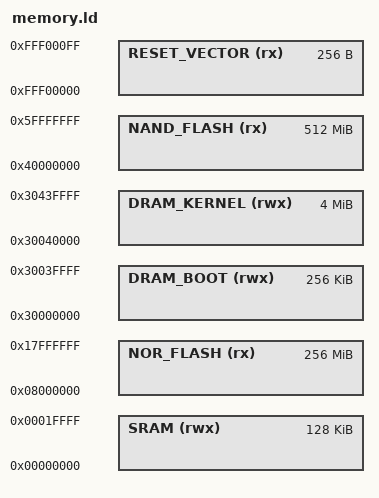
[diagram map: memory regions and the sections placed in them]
/* Memory layout - ARM Cortex-A8 OMAP3530 */

MEMORY
{
  RESET_VECTOR (rx)  : ORIGIN = 0xFFF00000, LENGTH = 0x100
  SRAM (rwx)         : ORIGIN = 0x00000000, LENGTH = 0x20000
  DRAM_BOOT (rwx)    : ORIGIN = 0x30000000, LENGTH = 0x40000
  DRAM_KERNEL (rwx)  : ORIGIN = 0x30040000, LENGTH = 0x400000
  NOR_FLASH (rx)     : ORIGIN = 0x08000000, LENGTH = 0x10000000
  NAND_FLASH (rx)    : ORIGIN = 0x40000000, LENGTH = 0x20000000
}

REGION_ALIAS("FLASH", NOR_FLASH);
REGION_ALIAS("RAM", SRAM);
REGION_ALIAS("BOOT_RAM", DRAM_BOOT);
REGION_ALIAS("MAIN_RAM", DRAM_KERNEL);
